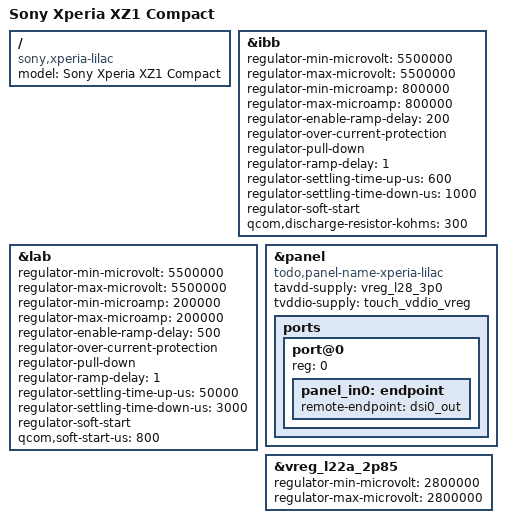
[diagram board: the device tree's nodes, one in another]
// SPDX-License-Identifier: BSD-3-Clause
/*
 * Copyright (c) 2020, AngeloGioacchino Del Regno
 *                     <angelogioacchino.delregno@somainline.org>
 */

/dts-v1/;

#include "msm8998-sony-xperia-yoshino.dtsi"

/ {
	model = "Sony Xperia XZ1 Compact";
	compatible = "sony,xperia-lilac", "qcom,msm8998";
};

&ibb {
	regulator-min-microvolt = <5500000>;
	regulator-max-microvolt = <5500000>;
	regulator-min-microamp = <800000>;
	regulator-max-microamp = <800000>;
	regulator-enable-ramp-delay = <200>;
	regulator-over-current-protection;
	regulator-pull-down;
	regulator-ramp-delay = <1>;
	regulator-settling-time-up-us = <600>;
	regulator-settling-time-down-us = <1000>;
	regulator-soft-start;
	qcom,discharge-resistor-kohms = <300>;
};

&lab {
	regulator-min-microvolt = <5500000>;
	regulator-max-microvolt = <5500000>;
	regulator-min-microamp = <200000>;
	regulator-max-microamp = <200000>;
	regulator-enable-ramp-delay = <500>;
	regulator-over-current-protection;
	regulator-pull-down;
	regulator-ramp-delay = <1>;
	regulator-settling-time-up-us = <50000>;
	regulator-settling-time-down-us = <3000>;
	regulator-soft-start;
	qcom,soft-start-us = <800>;
};

&panel {
	compatible = "todo,panel-name-xperia-lilac"; // TODO

	tavdd-supply = <&vreg_l28_3p0>;
	tvddio-supply = <&touch_vddio_vreg>;

	ports {
		#address-cells = <1>;
		#size-cells = <0>;

		port@0 {
			reg = <0>;
			panel_in0: endpoint {
				remote-endpoint = <&dsi0_out>;
			};
		};
	};
};

&vreg_l22a_2p85 {
	regulator-min-microvolt = <2800000>;
	regulator-max-microvolt = <2800000>;
};
